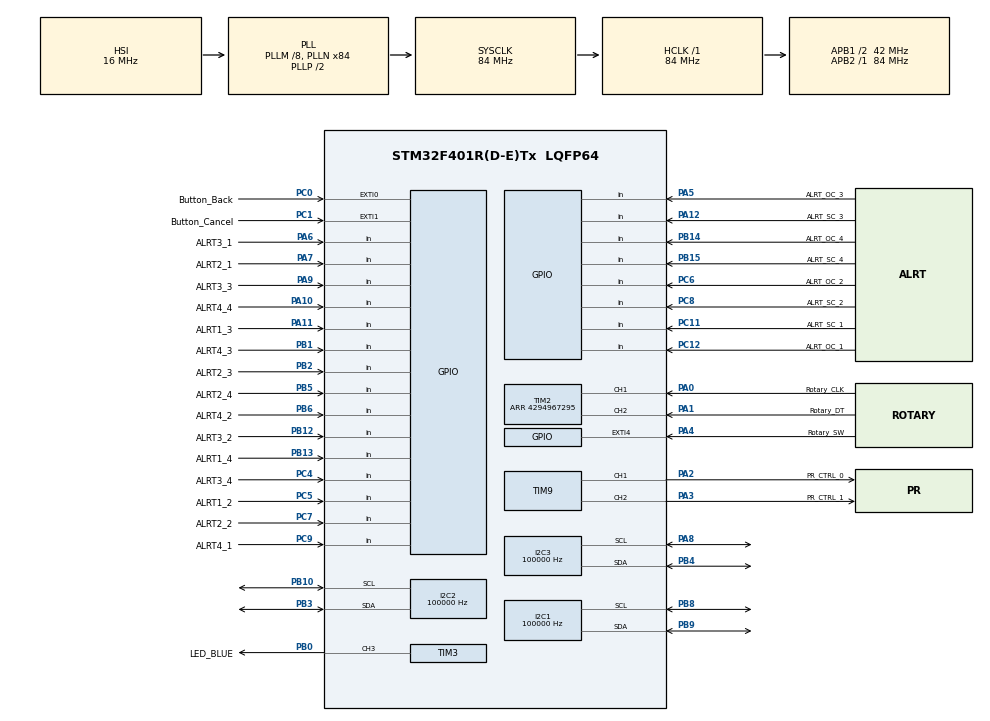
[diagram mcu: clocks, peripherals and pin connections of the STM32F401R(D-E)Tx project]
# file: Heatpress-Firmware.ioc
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Dma.I2C1_RX.0.Direction=DMA_PERIPH_TO_MEMORY
Dma.I2C1_RX.0.FIFOMode=DMA_FIFOMODE_DISABLE
Dma.I2C1_RX.0.Instance=DMA1_Stream0
Dma.I2C1_RX.0.MemDataAlignment=DMA_MDATAALIGN_BYTE
Dma.I2C1_RX.0.MemInc=DMA_MINC_ENABLE
Dma.I2C1_RX.0.Mode=DMA_NORMAL
Dma.I2C1_RX.0.PeriphDataAlignment=DMA_PDATAALIGN_BYTE
Dma.I2C1_RX.0.PeriphInc=DMA_PINC_DISABLE
Dma.I2C1_RX.0.Priority=DMA_PRIORITY_MEDIUM
Dma.I2C3_RX.1.Direction=DMA_PERIPH_TO_MEMORY
Dma.I2C3_RX.1.FIFOMode=DMA_FIFOMODE_DISABLE
Dma.I2C3_RX.1.Instance=DMA1_Stream1
Dma.I2C3_RX.1.MemDataAlignment=DMA_MDATAALIGN_BYTE
Dma.I2C3_RX.1.MemInc=DMA_MINC_ENABLE
Dma.I2C3_RX.1.Mode=DMA_NORMAL
Dma.I2C3_RX.1.PeriphDataAlignment=DMA_PDATAALIGN_BYTE
Dma.I2C3_RX.1.PeriphInc=DMA_PINC_DISABLE
Dma.I2C3_RX.1.Priority=DMA_PRIORITY_LOW
Dma.Request0=I2C1_RX
Dma.Request1=I2C3_RX
I2C1.ClockSpeed=100000
I2C1.DualAddressMode=I2C_DUALADDRESS_DISABLE
I2C1.NoStretchMode=I2C_NOSTRETCH_DISABLE
I2C2.ClockSpeed=100000
I2C2.I2C_Mode=I2C_Standard
I2C3.ClockSpeed=100000
Mcu.Family=STM32F4
Mcu.Name=STM32F401R(D-E)Tx
Mcu.Package=LQFP64
NVIC.DMA1_Stream0_IRQn=true\:0\:0\:false\:false\:true\:false\:true\:true
NVIC.DMA1_Stream1_IRQn=true\:0\:0\:false\:false\:true\:false\:true\:true
NVIC.EXTI0_IRQn=true\:0\:0\:false\:false\:true\:true\:true\:true
NVIC.EXTI1_IRQn=true\:0\:0\:false\:false\:true\:true\:true\:true
NVIC.EXTI4_IRQn=true\:0\:0\:false\:false\:true\:true\:true\:true
NVIC.PriorityGroup=NVIC_PRIORITYGROUP_0
NVIC.TIM2_IRQn=true\:0\:0\:false\:false\:true\:true\:true\:true
NVIC.TIM4_IRQn=true\:0\:0\:false\:false\:true\:true\:true\:true
NVIC.TIM5_IRQn=true\:0\:0\:false\:false\:true\:true\:true\:true
PA0-WKUP.GPIO_Label=Rotary_CLK
PA0-WKUP.Signal=S_TIM2_CH1_ETR
PA1.GPIO_Label=Rotary_DT
PA1.Signal=S_TIM2_CH2
PA10.GPIO_Label=ALRT4_4
PA10.Signal=GPIO_Input
PA11.GPIO_Label=ALRT1_3
PA11.Signal=GPIO_Input
PA12.GPIO_Label=ALRT_SC_3
PA12.Signal=GPIO_Input
PA13.GPIO_Label=TMS
PA13.Mode=Serial_Wire
PA13.Signal=SYS_JTMS-SWDIO
PA14.GPIO_Label=TCK
PA14.Mode=Serial_Wire
PA14.Signal=SYS_JTCK-SWCLK
PA2.GPIO_Label=PR_CTRL_0
PA2.Signal=S_TIM9_CH1
PA3.GPIO_Label=PR_CTRL_1
PA3.Signal=S_TIM9_CH2
PA4.GPIO_Label=Rotary_SW
PA4.GPIO_ModeDefaultEXTI=GPIO_MODE_IT_RISING_FALLING
PA4.Signal=GPXTI4
PA5.GPIO_Label=ALRT_OC_3
PA5.Signal=GPIO_Input
PA6.GPIO_Label=ALRT3_1
PA6.Signal=GPIO_Input
PA7.GPIO_Label=ALRT2_1
PA7.Signal=GPIO_Input
PA8.Mode=I2C
PA8.Signal=I2C3_SCL
PA9.GPIO_Label=ALRT3_3
PA9.Signal=GPIO_Input
PB0.GPIO_Label=LED_BLUE
PB0.Signal=S_TIM3_CH3
PB1.GPIO_Label=ALRT4_3
PB1.Signal=GPIO_Input
PB10.Mode=I2C
PB10.Signal=I2C2_SCL
PB12.GPIO_Label=ALRT3_2
PB12.Signal=GPIO_Input
PB13.GPIO_Label=ALRT1_4
PB13.Signal=GPIO_Input
PB14.GPIO_Label=ALRT_OC_4
PB14.Signal=GPIO_Input
PB15.GPIO_Label=ALRT_SC_4
PB15.Signal=GPIO_Input
PB2.GPIO_Label=ALRT2_3
PB2.Signal=GPIO_Input
PB3.Mode=I2C
PB3.Signal=I2C2_SDA
PB4.Mode=I2C
PB4.Signal=I2C3_SDA
PB5.GPIO_Label=ALRT2_4
PB5.Signal=GPIO_Input
PB6.GPIO_Label=ALRT4_2
PB6.Signal=GPIO_Input
PB8.GPIO_Pu=GPIO_NOPULL
PB8.Mode=I2C
PB8.Signal=I2C1_SCL
PB9.GPIO_Pu=GPIO_NOPULL
PB9.Mode=I2C
PB9.Signal=I2C1_SDA
PC0.GPIO_Label=Button_Back
PC0.GPIO_ModeDefaultEXTI=GPIO_MODE_IT_RISING_FALLING
PC0.GPIO_PuPd=GPIO_PULLUP
PC0.Signal=GPXTI0
PC1.GPIO_Label=Button_Cancel
PC1.GPIO_ModeDefaultEXTI=GPIO_MODE_IT_RISING_FALLING
PC1.GPIO_PuPd=GPIO_PULLUP
PC1.Signal=GPXTI1
PC11.GPIO_Label=ALRT_SC_1
PC11.Signal=GPIO_Input
PC12.GPIO_Label=ALRT_OC_1
PC12.Signal=GPIO_Input
PC14-OSC32_IN.Mode=LSE-External-Oscillator
PC14-OSC32_IN.Signal=RCC_OSC32_IN
PC15-OSC32_OUT.Mode=LSE-External-Oscillator
PC15-OSC32_OUT.Signal=RCC_OSC32_OUT
PC4.GPIO_Label=ALRT3_4
PC4.Signal=GPIO_Input
PC5.GPIO_Label=ALRT1_2
PC5.Signal=GPIO_Input
PC6.GPIO_Label=ALRT_OC_2
PC6.Signal=GPIO_Input
PC7.GPIO_Label=ALRT2_2
PC7.Signal=GPIO_Input
PC8.GPIO_Label=ALRT_SC_2
PC8.Signal=GPIO_Input
PC9.GPIO_Label=ALRT4_1
PC9.Signal=GPIO_Input
PH0\ -\ OSC_IN.Mode=HSE-External-Clock-Source
PH0\ -\ OSC_IN.Signal=RCC_OSC_IN
PH1\ -\ OSC_OUT.Mode=HSE-External-Clock-Source
PH1\ -\ OSC_OUT.Signal=RCC_OSC_OUT
ProjectManager.HeapSize=0x200
ProjectManager.StackSize=0x400
ProjectManager.TargetToolchain=STM32CubeIDE
RCC.48MHZClocksFreq_Value=24000000
RCC.AHBFreq_Value=84000000
RCC.APB1CLKDivider=RCC_HCLK_DIV2
RCC.APB1Freq_Value=42000000
RCC.APB1TimFreq_Value=84000000
RCC.APB2Freq_Value=84000000
RCC.APB2TimFreq_Value=84000000
RCC.CortexFreq_Value=84000000
RCC.HCLKFreq_Value=84000000
RCC.HSE_VALUE=8000000
RCC.HSI_VALUE=16000000
RCC.PLLM=8
RCC.PLLN=84
RCC.PLLQ=7
RCC.RCC_RTC_Clock_Source=RCC_RTCCLKSOURCE_LSI
RCC.RCC_RTC_Clock_SourceVirtual=RCC_RTCCLKSOURCE_LSI
RCC.SYSCLKFreq_VALUE=84000000
RCC.SYSCLKSource=RCC_SYSCLKSOURCE_PLLCLK
RCC.VCOOutputFreq_Value=168000000
SH.S_TIM2_CH1_ETR.0=TIM2_CH1,Encoder_Interface
SH.S_TIM2_CH2.0=TIM2_CH2,Encoder_Interface
SH.S_TIM3_CH3.0=TIM3_CH3,PWM Generation3 CH3
SH.S_TIM9_CH1.0=TIM9_CH1,PWM Generation1 CH1
SH.S_TIM9_CH2.0=TIM9_CH2,PWM Generation2 CH2
TIM2.AutoReloadPreload=TIM_AUTORELOAD_PRELOAD_ENABLE
TIM2.ClockDivision=TIM_CLOCKDIVISION_DIV1
TIM2.EncoderMode=TIM_ENCODERMODE_TI12
TIM2.IC1Filter=12
TIM2.IC1Prescaler=TIM_ICPSC_DIV1
TIM2.IC2Filter=12
TIM2.IC2Prescaler=TIM_ICPSC_DIV1
TIM2.Period=4294967295
TIM3.Channel-PWM\ Generation3\ CH3=TIM_CHANNEL_3
TIM3.TIM_MasterOutputTrigger=TIM_TRGO_RESET
TIM4.Period=1320
TIM4.Prescaler=1100
TIM4.TIM_MasterOutputTrigger=TIM_TRGO_RESET
TIM5.Period=1558
TIM5.Prescaler=1100
TIM9.Channel-PWM\ Generation1\ CH1=TIM_CHANNEL_1
TIM9.Channel-PWM\ Generation2\ CH2=TIM_CHANNEL_2
TIM9.OCMode_PWM-PWM\ Generation1\ CH1=TIM_OCMODE_PWM2
TIM9.OCMode_PWM-PWM\ Generation2\ CH2=TIM_OCMODE_PWM2
TIM9.OCPolarity_1=TIM_OCPOLARITY_LOW
TIM9.OCPolarity_2=TIM_OCPOLARITY_LOW
VP_TIM4_VS_ClockSourceINT.Mode=Internal
VP_TIM5_VS_ClockSourceINT.Mode=Internal
VP_TIM9_VS_ClockSourceINT.Mode=Internal
board=NUCLEO-F401RE

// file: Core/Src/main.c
/* USER CODE BEGIN Header */
/**
 ******************************************************************************
 * @file           : main.c
 * @brief          : Main program body
 ******************************************************************************
 * @attention
 *
 * Copyright (c) 2024 STMicroelectronics.
 * All rights reserved.
 *
 * This software is licensed under terms that can be found in the LICENSE file
 * in the root directory of this software component.
 * If no LICENSE file comes with this software, it is provided AS-IS.
 *
 ******************************************************************************
 */
/* USER CODE END Header */
#include "main.h"

/* USER CODE BEGIN Includes */

#include <stdint.h>
#include <stdio.h>

#include "run.h"

/* USER CODE END Includes */

I2C_HandleTypeDef hi2c1;
I2C_HandleTypeDef hi2c2;
I2C_HandleTypeDef hi2c3;
DMA_HandleTypeDef hdma_i2c1_rx;
DMA_HandleTypeDef hdma_i2c3_rx;

TIM_HandleTypeDef htim2;
TIM_HandleTypeDef htim3;
TIM_HandleTypeDef htim4;
TIM_HandleTypeDef htim5;
TIM_HandleTypeDef htim9;

void SystemClock_Config(void);
static void MX_GPIO_Init(void);
static void MX_DMA_Init(void);
static void MX_I2C1_Init(void);
static void MX_I2C3_Init(void);
static void MX_I2C2_Init(void);
static void MX_TIM2_Init(void);
static void MX_TIM3_Init(void);
static void MX_TIM9_Init(void);
static void MX_TIM4_Init(void);
static void MX_TIM5_Init(void);

int main(void)
{

  /* MCU Configuration--------------------------------------------------------*/

  /* Reset of all peripherals, Initializes the Flash interface and the Systick. */
  HAL_Init();

  /* Configure the system clock */
  SystemClock_Config();

  /* Initialize all configured peripherals */
  MX_GPIO_Init();
  MX_DMA_Init();
  MX_I2C1_Init();
  MX_I2C3_Init();
  MX_I2C2_Init();
  MX_TIM2_Init();
  MX_TIM3_Init();
  MX_TIM9_Init();
  MX_TIM4_Init();
  MX_TIM5_Init();
  /* USER CODE BEGIN 2 */

    //  int _write(int file, char *ptr, int len) {
    //      CDC_Transmit_FS((uint8_t*) ptr, len); return len;
    //  }

  /* USER CODE END 2 */

  /* Infinite loop */
  /* USER CODE BEGIN WHILE */

    run();

    while (1) {
    /* USER CODE END WHILE */

    /* USER CODE BEGIN 3 */

        HAL_Delay(500);
    }
  /* USER CODE END 3 */
}

void SystemClock_Config(void)
{
  RCC_OscInitTypeDef RCC_OscInitStruct = {0};
  RCC_ClkInitTypeDef RCC_ClkInitStruct = {0};

  /** Configure the main internal regulator output voltage
  */
  __HAL_RCC_PWR_CLK_ENABLE();
  __HAL_PWR_VOLTAGESCALING_CONFIG(PWR_REGULATOR_VOLTAGE_SCALE2);

  /** Initializes the RCC Oscillators according to the specified parameters
  * in the RCC_OscInitTypeDef structure.
  */
  RCC_OscInitStruct.OscillatorType = RCC_OSCILLATORTYPE_HSI;
  RCC_OscInitStruct.HSIState = RCC_HSI_ON;
  RCC_OscInitStruct.HSICalibrationValue = RCC_HSICALIBRATION_DEFAULT;
  RCC_OscInitStruct.PLL.PLLState = RCC_PLL_ON;
  RCC_OscInitStruct.PLL.PLLSource = RCC_PLLSOURCE_HSI;
  RCC_OscInitStruct.PLL.PLLM = 8;
  RCC_OscInitStruct.PLL.PLLN = 84;
  RCC_OscInitStruct.PLL.PLLP = RCC_PLLP_DIV2;
  RCC_OscInitStruct.PLL.PLLQ = 7;
  if (HAL_RCC_OscConfig(&RCC_OscInitStruct) != HAL_OK)
  {
    Error_Handler();
  }

  /** Initializes the CPU, AHB and APB buses clocks
  */
  RCC_ClkInitStruct.ClockType = RCC_CLOCKTYPE_HCLK|RCC_CLOCKTYPE_SYSCLK
                              |RCC_CLOCKTYPE_PCLK1|RCC_CLOCKTYPE_PCLK2;
  RCC_ClkInitStruct.SYSCLKSource = RCC_SYSCLKSOURCE_PLLCLK;
  RCC_ClkInitStruct.AHBCLKDivider = RCC_SYSCLK_DIV1;
  RCC_ClkInitStruct.APB1CLKDivider = RCC_HCLK_DIV2;
  RCC_ClkInitStruct.APB2CLKDivider = RCC_HCLK_DIV1;

  if (HAL_RCC_ClockConfig(&RCC_ClkInitStruct, FLASH_LATENCY_2) != HAL_OK)
  {
    Error_Handler();
  }
}

static void MX_I2C1_Init(void)
{

  hi2c1.Instance = I2C1;
  hi2c1.Init.ClockSpeed = 100000;
  hi2c1.Init.DutyCycle = I2C_DUTYCYCLE_2;
  hi2c1.Init.OwnAddress1 = 0;
  hi2c1.Init.AddressingMode = I2C_ADDRESSINGMODE_7BIT;
  hi2c1.Init.DualAddressMode = I2C_DUALADDRESS_DISABLE;
  hi2c1.Init.OwnAddress2 = 0;
  hi2c1.Init.GeneralCallMode = I2C_GENERALCALL_DISABLE;
  hi2c1.Init.NoStretchMode = I2C_NOSTRETCH_DISABLE;
  if (HAL_I2C_Init(&hi2c1) != HAL_OK)
  {
    Error_Handler();
  }

}

static void MX_I2C2_Init(void)
{

  hi2c2.Instance = I2C2;
  hi2c2.Init.ClockSpeed = 100000;
  hi2c2.Init.DutyCycle = I2C_DUTYCYCLE_2;
  hi2c2.Init.OwnAddress1 = 0;
  hi2c2.Init.AddressingMode = I2C_ADDRESSINGMODE_7BIT;
  hi2c2.Init.DualAddressMode = I2C_DUALADDRESS_DISABLE;
  hi2c2.Init.OwnAddress2 = 0;
  hi2c2.Init.GeneralCallMode = I2C_GENERALCALL_DISABLE;
  hi2c2.Init.NoStretchMode = I2C_NOSTRETCH_DISABLE;
  if (HAL_I2C_Init(&hi2c2) != HAL_OK)
  {
    Error_Handler();
  }

}

static void MX_I2C3_Init(void)
{

  hi2c3.Instance = I2C3;
  hi2c3.Init.ClockSpeed = 100000;
  hi2c3.Init.DutyCycle = I2C_DUTYCYCLE_2;
  hi2c3.Init.OwnAddress1 = 0;
  hi2c3.Init.AddressingMode = I2C_ADDRESSINGMODE_7BIT;
  hi2c3.Init.DualAddressMode = I2C_DUALADDRESS_DISABLE;
  hi2c3.Init.OwnAddress2 = 0;
  hi2c3.Init.GeneralCallMode = I2C_GENERALCALL_DISABLE;
  hi2c3.Init.NoStretchMode = I2C_NOSTRETCH_DISABLE;
  if (HAL_I2C_Init(&hi2c3) != HAL_OK)
  {
    Error_Handler();
  }

}

static void MX_TIM2_Init(void)
{

  TIM_Encoder_InitTypeDef sConfig = {0};
  TIM_MasterConfigTypeDef sMasterConfig = {0};

  htim2.Instance = TIM2;
  htim2.Init.Prescaler = 0;
  htim2.Init.CounterMode = TIM_COUNTERMODE_UP;
  htim2.Init.Period = 4294967295;
  htim2.Init.ClockDivision = TIM_CLOCKDIVISION_DIV1;
  htim2.Init.AutoReloadPreload = TIM_AUTORELOAD_PRELOAD_ENABLE;
  sConfig.EncoderMode = TIM_ENCODERMODE_TI12;
  sConfig.IC1Polarity = TIM_ICPOLARITY_RISING;
  sConfig.IC1Selection = TIM_ICSELECTION_DIRECTTI;
  sConfig.IC1Prescaler = TIM_ICPSC_DIV1;
  sConfig.IC1Filter = 12;
  sConfig.IC2Polarity = TIM_ICPOLARITY_RISING;
  sConfig.IC2Selection = TIM_ICSELECTION_DIRECTTI;
  sConfig.IC2Prescaler = TIM_ICPSC_DIV1;
  sConfig.IC2Filter = 12;
  if (HAL_TIM_Encoder_Init(&htim2, &sConfig) != HAL_OK)
  {
    Error_Handler();
  }
  sMasterConfig.MasterOutputTrigger = TIM_TRGO_RESET;
  sMasterConfig.MasterSlaveMode = TIM_MASTERSLAVEMODE_DISABLE;
  if (HAL_TIMEx_MasterConfigSynchronization(&htim2, &sMasterConfig) != HAL_OK)
  {
    Error_Handler();
  }

}

static void MX_TIM3_Init(void)
{

  TIM_MasterConfigTypeDef sMasterConfig = {0};
  TIM_OC_InitTypeDef sConfigOC = {0};

  htim3.Instance = TIM3;
  htim3.Init.Prescaler = 0;
  htim3.Init.CounterMode = TIM_COUNTERMODE_UP;
  htim3.Init.Period = 65535;
  htim3.Init.ClockDivision = TIM_CLOCKDIVISION_DIV1;
  htim3.Init.AutoReloadPreload = TIM_AUTORELOAD_PRELOAD_DISABLE;
  if (HAL_TIM_PWM_Init(&htim3) != HAL_OK)
  {
    Error_Handler();
  }
  sMasterConfig.MasterOutputTrigger = TIM_TRGO_RESET;
  sMasterConfig.MasterSlaveMode = TIM_MASTERSLAVEMODE_DISABLE;
  if (HAL_TIMEx_MasterConfigSynchronization(&htim3, &sMasterConfig) != HAL_OK)
  {
    Error_Handler();
  }
  sConfigOC.OCMode = TIM_OCMODE_PWM1;
  sConfigOC.Pulse = 0;
  sConfigOC.OCPolarity = TIM_OCPOLARITY_HIGH;
  sConfigOC.OCFastMode = TIM_OCFAST_DISABLE;
  if (HAL_TIM_PWM_ConfigChannel(&htim3, &sConfigOC, TIM_CHANNEL_3) != HAL_OK)
  {
    Error_Handler();
  }
  HAL_TIM_MspPostInit(&htim3);

}

static void MX_TIM4_Init(void)
{

  TIM_ClockConfigTypeDef sClockSourceConfig = {0};
  TIM_MasterConfigTypeDef sMasterConfig = {0};

  htim4.Instance = TIM4;
  htim4.Init.Prescaler = 1100;
  htim4.Init.CounterMode = TIM_COUNTERMODE_UP;
  htim4.Init.Period = 1320;
  htim4.Init.ClockDivision = TIM_CLOCKDIVISION_DIV1;
  htim4.Init.AutoReloadPreload = TIM_AUTORELOAD_PRELOAD_DISABLE;
  if (HAL_TIM_Base_Init(&htim4) != HAL_OK)
  {
    Error_Handler();
  }
  sClockSourceConfig.ClockSource = TIM_CLOCKSOURCE_INTERNAL;
  if (HAL_TIM_ConfigClockSource(&htim4, &sClockSourceConfig) != HAL_OK)
  {
    Error_Handler();
  }
  sMasterConfig.MasterOutputTrigger = TIM_TRGO_RESET;
  sMasterConfig.MasterSlaveMode = TIM_MASTERSLAVEMODE_DISABLE;
  if (HAL_TIMEx_MasterConfigSynchronization(&htim4, &sMasterConfig) != HAL_OK)
  {
    Error_Handler();
  }

}

static void MX_TIM5_Init(void)
{

  TIM_ClockConfigTypeDef sClockSourceConfig = {0};
  TIM_MasterConfigTypeDef sMasterConfig = {0};

  htim5.Instance = TIM5;
  htim5.Init.Prescaler = 1100;
  htim5.Init.CounterMode = TIM_COUNTERMODE_UP;
  htim5.Init.Period = 1558;
  htim5.Init.ClockDivision = TIM_CLOCKDIVISION_DIV1;
  htim5.Init.AutoReloadPreload = TIM_AUTORELOAD_PRELOAD_DISABLE;
  if (HAL_TIM_Base_Init(&htim5) != HAL_OK)
  {
    Error_Handler();
  }
  sClockSourceConfig.ClockSource = TIM_CLOCKSOURCE_INTERNAL;
  if (HAL_TIM_ConfigClockSource(&htim5, &sClockSourceConfig) != HAL_OK)
  {
    Error_Handler();
  }
  sMasterConfig.MasterOutputTrigger = TIM_TRGO_RESET;
  sMasterConfig.MasterSlaveMode = TIM_MASTERSLAVEMODE_DISABLE;
  if (HAL_TIMEx_MasterConfigSynchronization(&htim5, &sMasterConfig) != HAL_OK)
  {
    Error_Handler();
  }

}

static void MX_TIM9_Init(void)
{

  TIM_ClockConfigTypeDef sClockSourceConfig = {0};
  TIM_OC_InitTypeDef sConfigOC = {0};

  htim9.Instance = TIM9;
  htim9.Init.Prescaler = 0;
  htim9.Init.CounterMode = TIM_COUNTERMODE_UP;
  htim9.Init.Period = 65535;
  htim9.Init.ClockDivision = TIM_CLOCKDIVISION_DIV1;
  htim9.Init.AutoReloadPreload = TIM_AUTORELOAD_PRELOAD_DISABLE;
  if (HAL_TIM_Base_Init(&htim9) != HAL_OK)
  {
    Error_Handler();
  }
  sClockSourceConfig.ClockSource = TIM_CLOCKSOURCE_INTERNAL;
  if (HAL_TIM_ConfigClockSource(&htim9, &sClockSourceConfig) != HAL_OK)
  {
    Error_Handler();
  }
  if (HAL_TIM_PWM_Init(&htim9) != HAL_OK)
  {
    Error_Handler();
  }
  sConfigOC.OCMode = TIM_OCMODE_PWM2;
  sConfigOC.Pulse = 0;
  sConfigOC.OCPolarity = TIM_OCPOLARITY_LOW;
  sConfigOC.OCFastMode = TIM_OCFAST_DISABLE;
  if (HAL_TIM_PWM_ConfigChannel(&htim9, &sConfigOC, TIM_CHANNEL_1) != HAL_OK)
  {
    Error_Handler();
  }
  if (HAL_TIM_PWM_ConfigChannel(&htim9, &sConfigOC, TIM_CHANNEL_2) != HAL_OK)
  {
    Error_Handler();
  }
  HAL_TIM_MspPostInit(&htim9);

}

static void MX_DMA_Init(void)
{

  /* DMA controller clock enable */
  __HAL_RCC_DMA1_CLK_ENABLE();

  /* DMA interrupt init */
  /* DMA1_Stream0_IRQn interrupt configuration */
  HAL_NVIC_SetPriority(DMA1_Stream0_IRQn, 0, 0);
  HAL_NVIC_EnableIRQ(DMA1_Stream0_IRQn);
  /* DMA1_Stream1_IRQn interrupt configuration */
  HAL_NVIC_SetPriority(DMA1_Stream1_IRQn, 0, 0);
  HAL_NVIC_EnableIRQ(DMA1_Stream1_IRQn);

}

static void MX_GPIO_Init(void)
{
  GPIO_InitTypeDef GPIO_InitStruct = {0};

  /* GPIO Ports Clock Enable */
  __HAL_RCC_GPIOC_CLK_ENABLE();
  __HAL_RCC_GPIOH_CLK_ENABLE();
  __HAL_RCC_GPIOA_CLK_ENABLE();
  __HAL_RCC_GPIOB_CLK_ENABLE();
  __HAL_RCC_GPIOD_CLK_ENABLE();

  /*Configure GPIO pins : PC13 PC2 PC3 PC10 */
  GPIO_InitStruct.Pin = GPIO_PIN_13|GPIO_PIN_2|GPIO_PIN_3|GPIO_PIN_10;
  GPIO_InitStruct.Mode = GPIO_MODE_ANALOG;
  GPIO_InitStruct.Pull = GPIO_NOPULL;
  HAL_GPIO_Init(GPIOC, &GPIO_InitStruct);

  /*Configure GPIO pins : Button_Back_Pin Button_Cancel_Pin */
  GPIO_InitStruct.Pin = Button_Back_Pin|Button_Cancel_Pin;
  GPIO_InitStruct.Mode = GPIO_MODE_IT_RISING_FALLING;
  GPIO_InitStruct.Pull = GPIO_PULLUP;
  HAL_GPIO_Init(GPIOC, &GPIO_InitStruct);

  /*Configure GPIO pin : Rotary_SW_Pin */
  GPIO_InitStruct.Pin = Rotary_SW_Pin;
  GPIO_InitStruct.Mode = GPIO_MODE_IT_RISING_FALLING;
  GPIO_InitStruct.Pull = GPIO_NOPULL;
  HAL_GPIO_Init(Rotary_SW_GPIO_Port, &GPIO_InitStruct);

  /*Configure GPIO pins : ALRT_OC_3_Pin ALRT3_1_Pin ALRT2_1_Pin ALRT3_3_Pin
                           ALRT4_4_Pin ALRT1_3_Pin ALRT_SC_3_Pin */
  GPIO_InitStruct.Pin = ALRT_OC_3_Pin|ALRT3_1_Pin|ALRT2_1_Pin|ALRT3_3_Pin
                          |ALRT4_4_Pin|ALRT1_3_Pin|ALRT_SC_3_Pin;
  GPIO_InitStruct.Mode = GPIO_MODE_INPUT;
  GPIO_InitStruct.Pull = GPIO_NOPULL;
  HAL_GPIO_Init(GPIOA, &GPIO_InitStruct);

  /*Configure GPIO pins : ALRT3_4_Pin ALRT1_2_Pin ALRT_OC_2_Pin ALRT2_2_Pin
                           ALRT_SC_2_Pin ALRT4_1_Pin ALRT_SC_1_Pin ALRT_OC_1_Pin */
  GPIO_InitStruct.Pin = ALRT3_4_Pin|ALRT1_2_Pin|ALRT_OC_2_Pin|ALRT2_2_Pin
                          |ALRT_SC_2_Pin|ALRT4_1_Pin|ALRT_SC_1_Pin|ALRT_OC_1_Pin;
  GPIO_InitStruct.Mode = GPIO_MODE_INPUT;
  GPIO_InitStruct.Pull = GPIO_NOPULL;
  HAL_GPIO_Init(GPIOC, &GPIO_InitStruct);

  /*Configure GPIO pins : ALRT4_3_Pin ALRT2_3_Pin ALRT3_2_Pin ALRT1_4_Pin
                           ALRT_OC_4_Pin ALRT_SC_4_Pin ALRT2_4_Pin ALRT4_2_Pin */
  GPIO_InitStruct.Pin = ALRT4_3_Pin|ALRT2_3_Pin|ALRT3_2_Pin|ALRT1_4_Pin
                          |ALRT_OC_4_Pin|ALRT_SC_4_Pin|ALRT2_4_Pin|ALRT4_2_Pin;
  GPIO_InitStruct.Mode = GPIO_MODE_INPUT;
  GPIO_InitStruct.Pull = GPIO_NOPULL;
  HAL_GPIO_Init(GPIOB, &GPIO_InitStruct);

  /*Configure GPIO pin : PA15 */
  GPIO_InitStruct.Pin = GPIO_PIN_15;
  GPIO_InitStruct.Mode = GPIO_MODE_ANALOG;
  GPIO_InitStruct.Pull = GPIO_NOPULL;
  HAL_GPIO_Init(GPIOA, &GPIO_InitStruct);

  /*Configure GPIO pin : PD2 */
  GPIO_InitStruct.Pin = GPIO_PIN_2;
  GPIO_InitStruct.Mode = GPIO_MODE_ANALOG;
  GPIO_InitStruct.Pull = GPIO_NOPULL;
  HAL_GPIO_Init(GPIOD, &GPIO_InitStruct);

  /*Configure GPIO pin : PB7 */
  GPIO_InitStruct.Pin = GPIO_PIN_7;
  GPIO_InitStruct.Mode = GPIO_MODE_ANALOG;
  GPIO_InitStruct.Pull = GPIO_NOPULL;
  HAL_GPIO_Init(GPIOB, &GPIO_InitStruct);

  /* EXTI interrupt init*/
  HAL_NVIC_SetPriority(EXTI0_IRQn, 0, 0);
  HAL_NVIC_EnableIRQ(EXTI0_IRQn);

  HAL_NVIC_SetPriority(EXTI1_IRQn, 0, 0);
  HAL_NVIC_EnableIRQ(EXTI1_IRQn);

  HAL_NVIC_SetPriority(EXTI4_IRQn, 0, 0);
  HAL_NVIC_EnableIRQ(EXTI4_IRQn);

}

void Error_Handler(void)
{
  /* USER CODE BEGIN Error_Handler_Debug */
    /* User can add his own implementation to report the HAL error return state */
    __disable_irq();
    TIM9->CCR1 = 0;
    TIM9->CCR2 = 0;
    while (1) {
    }
  /* USER CODE END Error_Handler_Debug */
}
